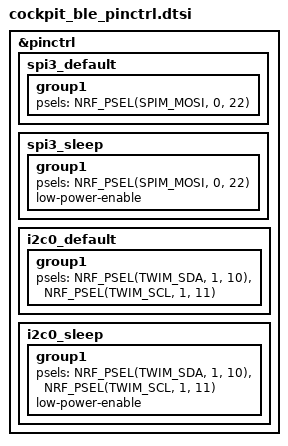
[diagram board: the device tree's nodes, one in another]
/*
* Copyright (c) 2022 The ZMK Contributors
* SPDX-License-Identifier: MIT
*/

&pinctrl {
        spi3_default: spi3_default {
        group1 {
                psels = <NRF_PSEL(SPIM_MOSI, 0, 22)>;

                };
        };

        spi3_sleep: spi3_sleep {
        group1 {
                psels = <NRF_PSEL(SPIM_MOSI, 0, 22)>;
                        low-power-enable;

                };
        };


        i2c0_default: i2c0_default {
                group1 {
                        psels = <NRF_PSEL(TWIM_SDA, 1, 10)>,
                                <NRF_PSEL(TWIM_SCL, 1, 11)>;
                };
        };

        i2c0_sleep: i2c0_sleep {
                group1 {
                        psels = <NRF_PSEL(TWIM_SDA, 1, 10)>,
                                <NRF_PSEL(TWIM_SCL, 1, 11)>;
                        low-power-enable;
                };
        };
};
